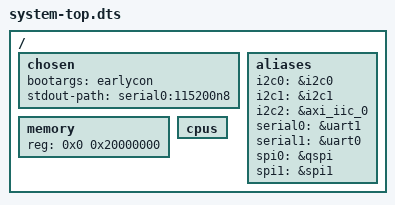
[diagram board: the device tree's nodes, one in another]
/*
 * CAUTION: This file is automatically generated by Xilinx.
 * Version:  
 * Today is: Wed Feb 20 13:51:34 2019
 */


/dts-v1/;
/include/ "zynq-7000.dtsi"
/include/ "pl.dtsi"
/include/ "pcw.dtsi"
/ {
	chosen {
		bootargs = "earlycon";
		stdout-path = "serial0:115200n8";
	};
	aliases {
		i2c0 = &i2c0;
		i2c1 = &i2c1;
		i2c2 = &axi_iic_0;
		serial0 = &uart1;
		serial1 = &uart0;
		spi0 = &qspi;
		spi1 = &spi1;
	};
	memory {
		device_type = "memory";
		reg = <0x0 0x20000000>;
	};
	cpus {
		/delete-node/ cpu@1 ;
	};
};
